# ATSAMA5D34 device description
Architecture: CORTEX-A5; Family: SAMA5
Registers are 32-bit, read-write, no defined reset value unless marked. A register's access mark holds for its fields unless they carry their own. Offsets are from the block's base; [hi:lo] are bit positions; {n}, {i} and the like mark numbered series; 'fields as' and 'values as' point back to an identical list.

## AIC — Advanced Interrupt Controller
Instances: AIC 0xFFFFF000
0x00 AIC_SSR — Source Select Register
  [6:0] INTSEL — Interrupt line Selection
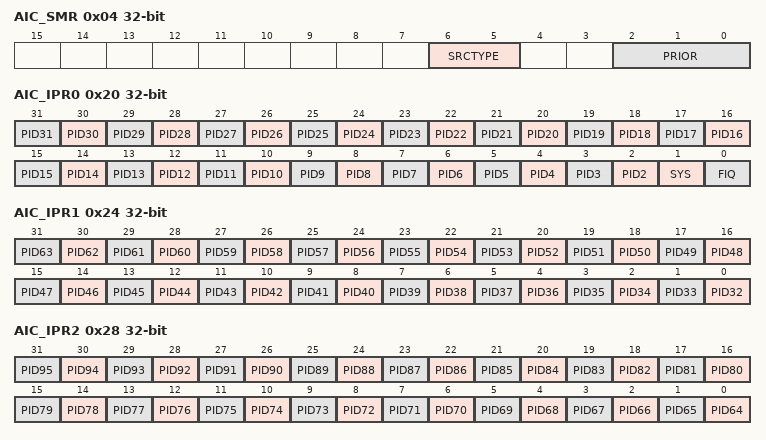
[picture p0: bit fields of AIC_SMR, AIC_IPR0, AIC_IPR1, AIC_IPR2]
0x04 AIC_SMR — Source Mode Register
  [6:5] SRCTYPE — Interrupt Source Type
    0=INT_LEVEL_SENSITIVE (High level Sensitive for internal sourceLow level Sensitive for external source); 1=INT_EDGE_TRIGGERED (Positive edge triggered for internal sourceNegative edge triggered for external source); 2=EXT_HIGH_LEVEL (High level Sensitive for internal sourceHigh level Sensitive for external source); 3=EXT_POSITIVE_EDGE (Positive edge triggered for internal sourcePositive edge triggered for external source)
  [2:0] PRIOR — Priority Level
0x08 AIC_SVR — Source Vector Register
  [31:0] VECTOR — Source Vector
0x10 AIC_IVR ro — Interrupt Vector Register
  [31:0] IRQV
0x14 AIC_FVR ro — FIQ Interrupt Vector Register
  [31:0] FIQV — FIQ Vector Register
0x18 AIC_ISR ro — Interrupt Status Register
  [6:0] IRQID — Current Interrupt Identifier
0x20 AIC_IPR0 ro — Interrupt Pending Register 0
  [n] PID{n} (n=2..31) — Interrupt Pending
  [1] SYS — Interrupt Pending
  [0] FIQ — Interrupt Pending
0x24 AIC_IPR1 ro — Interrupt Pending Register 1
  [n-32] PID{n} (n=32..63) — Interrupt Pending
0x28 AIC_IPR2 ro — Interrupt Pending Register 2
  [n-64] PID{n} (n=64..95) — Interrupt Pending
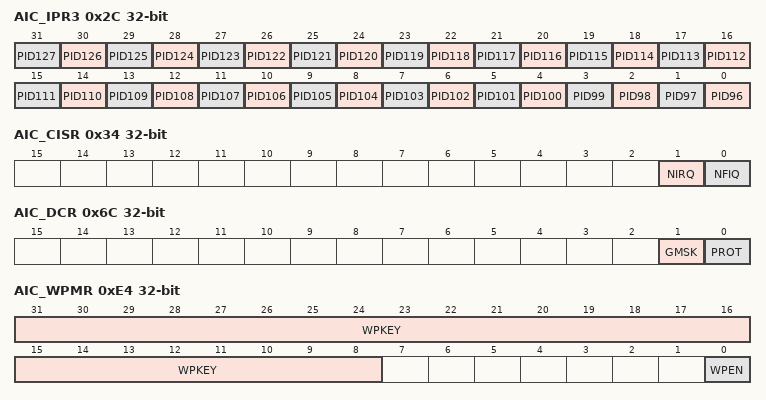
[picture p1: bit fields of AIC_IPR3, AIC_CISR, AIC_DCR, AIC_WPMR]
0x2C AIC_IPR3 ro — Interrupt Pending Register 3
  [n-96] PID{n} (n=96..127) — Interrupt Pending
0x30 AIC_IMR ro — Interrupt Mask Register
  [0] INTM — Interrupt Mask
0x34 AIC_CISR ro — Core Interrupt Status Register
  [1] NIRQ — NIRQ Status
  [0] NFIQ — NFIQ Status
0x38 AIC_EOICR wo — End of Interrupt Command Register
0x3C AIC_SPU — Spurious Interrupt Vector Register
  [31:0] SIVR
0x40 AIC_IECR wo — Interrupt Enable Command Register
  [0] INTEN — Interrupt Enable
0x44 AIC_IDCR wo — Interrupt Disable Command Register
  [0] INTD — Interrupt Disable
0x48 AIC_ICCR wo — Interrupt Clear Command Register
  [0] INTCLR — Interrupt Clear
0x4C AIC_ISCR wo — Interrupt Set Command Register
  [0] INTSET — Interrupt Set
0x50 AIC_FFER wo — Fast Forcing Enable Register
  [0] FFEN — Fast Forcing Enable
0x54 AIC_FFDR wo — Fast Forcing Disable Register
  [0] FFDIS — Fast Forcing Disable
0x58 AIC_FFSR ro — Fast Forcing Status Register
  [0] FFS — Fast Forcing Status
0x6C AIC_DCR — Debug Control Register
  [1] GMSK — General Mask
  [0] PROT — Protection Mode
0xE4 AIC_WPMR — Write Protect Mode Register
  [31:8] WPKEY — Write Protect KEY
  [0] WPEN — Write Protect Enable
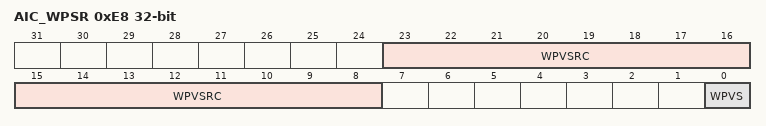
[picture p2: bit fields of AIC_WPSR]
0xE8 AIC_WPSR ro — Write Protect Status Register
  [23:8] WPVSRC — Write Protect Violation Source
  [0] WPVS — Write Protect Violation Status

## AXIMX — AXI MATRIX
Instances: AXIMX 0x00800000
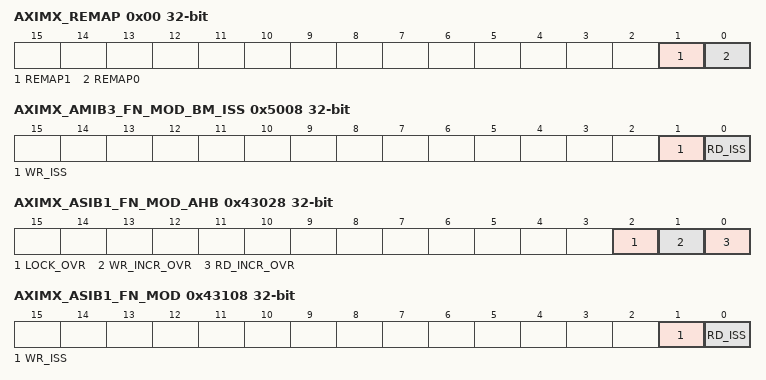
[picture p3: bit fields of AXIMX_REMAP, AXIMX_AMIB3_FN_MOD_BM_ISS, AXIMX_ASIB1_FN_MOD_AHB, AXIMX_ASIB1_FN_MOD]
0x00 AXIMX_REMAP wo — Remap Register
  [1] REMAP1 — Remap State 1
  [0] REMAP0 — Remap State 0
{0x1FC0+4i} AXIMX_PERIPH_ID{i} ro (i=4..7) — Peripheral ID Register {i}
  [7:0] ID — Peripheral ID
    1=Part Number; 4=4KB count, JEP106 continuation code; 179=JEP106[3:0, part number[11:8]; 182=Revision, JEP106 code flag, JEP106[6:4]
{0x1FE0+4i} AXIMX_PERIPH_ID{i} ro (i=0..3) — Peripheral ID Register {i}
  fields as AXIMX_PERIPH_ID4
{0x1FF0+4i} AXIMX_COMP_ID{i} ro (i=0..3) — Component ID Register {i}
  [7:0] ID — Component ID
0x5008 AXIMX_AMIB3_FN_MOD_BM_ISS — AMIB3 Bus Matrix Functionality Modification Register
  [1] WR_ISS — Write Issuing
  [0] RD_ISS — Read Issuing
0x5024 AXIMX_AMIB3_FN_MOD2 — AMIB3 Bypass Merge
  [0] BP_MRG — Bypass Merge
0x42100 AXIMX_ASIB0_READ_QOS — ASIB0 Read Channel QoS Register
  [3:0] RD_QOS — Read QoS
0x42104 AXIMX_ASIB0_WRITE_QOS — ASIB0 Write Channel QoS Register
  [3:0] WR_QOS — Write QoS
0x43028 AXIMX_ASIB1_FN_MOD_AHB — ASIB1 AHB Functionality Modification Register
  [2] LOCK_OVR — Lock Override
  [1] WR_INCR_OVR — Write INCR override
  [0] RD_INCR_OVR — Read INCR Override
0x43100 AXIMX_ASIB1_READ_QOS — ASIB1 Read Channel QoS Register
  [3:0] RD_QOS — Read QoS
0x43104 AXIMX_ASIB1_WRITE_QOS — ASIB1 Write Channel QoS Register
  [3:0] WR_QOS — Write QoS
0x43108 AXIMX_ASIB1_FN_MOD — ASIB1 Issuing Functionality Modification Register
  [1] WR_ISS — Write Issuing
  [0] RD_ISS — Read Issuing
